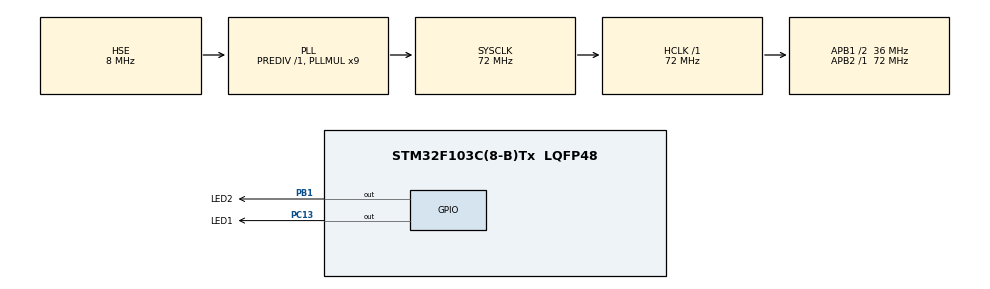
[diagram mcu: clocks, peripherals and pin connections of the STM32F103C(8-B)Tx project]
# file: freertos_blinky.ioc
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Mcu.Family=STM32F1
RCC.PLLSourceVirtual=RCC_PLLSOURCE_HSE
PC15-OSC32_OUT.Mode=LSE-External-Oscillator
FREERTOS.Tasks01=defaultTask,8,128,StartDefaultTask,Default,NULL,Dynamic,NULL,NULL
PD1-OSC_OUT.Mode=HSE-External-Oscillator
PC13-TAMPER-RTC.Signal=GPIO_Output
NVIC.TIM1_UP_IRQn=true\:0\:0\:false\:false\:true\:false\:false\:true
PD0-OSC_IN.Signal=RCC_OSC_IN
RCC.APB1CLKDivider=RCC_HCLK_DIV2
PC14-OSC32_IN.Signal=RCC_OSC32_IN
RCC.SYSCLKSource=RCC_SYSCLKSOURCE_PLLCLK
ProjectManager.StackSize=0x400
VP_FREERTOS_VS_CMSIS_V2.Mode=CMSIS_V2
PD1-OSC_OUT.Signal=RCC_OSC_OUT
PA13.Signal=SYS_JTMS-SWDIO
ProjectManager.TargetToolchain=STM32CubeIDE
RCC.HCLKFreq_Value=72000000
RCC.APB2TimFreq_Value=72000000
RCC.USBFreq_Value=72000000
PC15-OSC32_OUT.Signal=RCC_OSC32_OUT
RCC.AHBFreq_Value=72000000
PD0-OSC_IN.Mode=HSE-External-Oscillator
board=custom
PC13-TAMPER-RTC.GPIO_Label=LED1
RCC.PLLMUL=RCC_PLL_MUL9
RCC.APB2Freq_Value=72000000
PC14-OSC32_IN.Mode=LSE-External-Oscillator
PC13-TAMPER-RTC.PinState=GPIO_PIN_SET
PA14.Mode=Serial_Wire
VP_SYS_VS_tim1.Mode=TIM1
PB1.GPIO_Label=LED2
PA13.Mode=Serial_Wire
Mcu.Name=STM32F103C(8-B)Tx
PB1.PinState=GPIO_PIN_SET
RCC.SYSCLKFreq_VALUE=72000000
Mcu.Package=LQFP48
PB1.Signal=GPIO_Output
NVIC.TimeBase=TIM1_UP_IRQn
NVIC.TimeBaseIP=TIM1
PA14.Signal=SYS_JTCK-SWCLK
ProjectManager.HeapSize=0x200
NVIC.PriorityGroup=NVIC_PRIORITYGROUP_4
RCC.APB1TimFreq_Value=72000000
RCC.APB1Freq_Value=36000000

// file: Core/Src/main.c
/* USER CODE BEGIN Header */
/**
 ******************************************************************************
 * @file           : main.c
 * @brief          : Main program body
 ******************************************************************************
 * @attention
 *
 * <h2><center>&copy; Copyright (c) 2021 STMicroelectronics.
 * All rights reserved.</center></h2>
 *
 * This software component is licensed by ST under BSD 3-Clause license,
 * the "License"; You may not use this file except in compliance with the
 * License. You may obtain a copy of the License at:
 *                        opensource.org/licenses/BSD-3-Clause
 *
 ******************************************************************************
 */
/* USER CODE END Header */
#include "main.h"
#include "cmsis_os.h"

/* USER CODE BEGIN Includes */
#include "task.h"
/* USER CODE END Includes */

/* USER CODE BEGIN PTD */
typedef struct {
	GPIO_TypeDef *led_gpio_port;
	uint16_t led_gpio_pin;
	uint32_t tiempo;
} task_param_t;
/* USER CODE END PTD */

/* Definitions for defaultTask */
osThreadId_t defaultTaskHandle;
const osThreadAttr_t defaultTask_attributes = {
		.name = "defaultTask",
		.stack_size = 128 * 4,
		.priority = (osPriority_t) osPriorityLow,
};
/* USER CODE BEGIN PV */

static task_param_t task_param1 = {
		.led_gpio_port = LED1_GPIO_Port,
		.led_gpio_pin = LED1_Pin,
		.tiempo = 100
};

static task_param_t task_param2 = {
		.led_gpio_port = LED2_GPIO_Port,
		.led_gpio_pin = LED2_Pin,
		.tiempo = 700
};

/* USER CODE END PV */

void SystemClock_Config(void);
static void MX_GPIO_Init(void);
void StartDefaultTask(void *argument);

/* USER CODE BEGIN 0 */

static void task(void *a)
{
	task_param_t *task_param = (task_param_t *)a;

	while (1) {
		HAL_GPIO_TogglePin(task_param->led_gpio_port, task_param->led_gpio_pin);
		vTaskDelay(task_param->tiempo / portTICK_RATE_MS);
	}
}

/* USER CODE END 0 */

int main(void)
{

	/* MCU Configuration--------------------------------------------------------*/

	/* Reset of all peripherals, Initializes the Flash interface and the Systick. */
	HAL_Init();

	/* Configure the system clock */
	SystemClock_Config();

	/* Initialize all configured peripherals */
	MX_GPIO_Init();

	/* Init scheduler */
	osKernelInitialize();

	/* Create the thread(s) */
	/* creation of defaultTask */
	defaultTaskHandle = osThreadNew(StartDefaultTask, NULL, &defaultTask_attributes);

	/* USER CODE BEGIN RTOS_THREADS */
	xTaskCreate(task, (const char *)"task_1",
			configMINIMAL_STACK_SIZE*2, &task_param1, osPriorityNormal, 0);

	xTaskCreate(task, (const char *)"task_2",
			configMINIMAL_STACK_SIZE*2, &task_param2, osPriorityNormal, 0);
	/* USER CODE END RTOS_THREADS */

	/* Start scheduler */
	osKernelStart();

	/* We should never get here as control is now taken by the scheduler */
	/* Infinite loop */
	while (1)
	{

	}
}

void SystemClock_Config(void)
{
	RCC_OscInitTypeDef RCC_OscInitStruct = {0};
	RCC_ClkInitTypeDef RCC_ClkInitStruct = {0};

	/** Initializes the RCC Oscillators according to the specified parameters
	 * in the RCC_OscInitTypeDef structure.
	 */
	RCC_OscInitStruct.OscillatorType = RCC_OSCILLATORTYPE_HSE;
	RCC_OscInitStruct.HSEState = RCC_HSE_ON;
	RCC_OscInitStruct.HSEPredivValue = RCC_HSE_PREDIV_DIV1;
	RCC_OscInitStruct.HSIState = RCC_HSI_ON;
	RCC_OscInitStruct.PLL.PLLState = RCC_PLL_ON;
	RCC_OscInitStruct.PLL.PLLSource = RCC_PLLSOURCE_HSE;
	RCC_OscInitStruct.PLL.PLLMUL = RCC_PLL_MUL9;
	if (HAL_RCC_OscConfig(&RCC_OscInitStruct) != HAL_OK)
	{
		Error_Handler();
	}
	/** Initializes the CPU, AHB and APB buses clocks
	 */
	RCC_ClkInitStruct.ClockType = RCC_CLOCKTYPE_HCLK|RCC_CLOCKTYPE_SYSCLK
			|RCC_CLOCKTYPE_PCLK1|RCC_CLOCKTYPE_PCLK2;
	RCC_ClkInitStruct.SYSCLKSource = RCC_SYSCLKSOURCE_PLLCLK;
	RCC_ClkInitStruct.AHBCLKDivider = RCC_SYSCLK_DIV1;
	RCC_ClkInitStruct.APB1CLKDivider = RCC_HCLK_DIV2;
	RCC_ClkInitStruct.APB2CLKDivider = RCC_HCLK_DIV1;

	if (HAL_RCC_ClockConfig(&RCC_ClkInitStruct, FLASH_LATENCY_2) != HAL_OK)
	{
		Error_Handler();
	}
}

static void MX_GPIO_Init(void)
{
	GPIO_InitTypeDef GPIO_InitStruct = {0};

	/* GPIO Ports Clock Enable */
	__HAL_RCC_GPIOC_CLK_ENABLE();
	__HAL_RCC_GPIOD_CLK_ENABLE();
	__HAL_RCC_GPIOB_CLK_ENABLE();
	__HAL_RCC_GPIOA_CLK_ENABLE();

	/*Configure GPIO pin Output Level */
	HAL_GPIO_WritePin(LED1_GPIO_Port, LED1_Pin, GPIO_PIN_SET);

	/*Configure GPIO pin Output Level */
	HAL_GPIO_WritePin(LED2_GPIO_Port, LED2_Pin, GPIO_PIN_SET);

	/*Configure GPIO pin : LED1_Pin */
	GPIO_InitStruct.Pin = LED1_Pin;
	GPIO_InitStruct.Mode = GPIO_MODE_OUTPUT_PP;
	GPIO_InitStruct.Pull = GPIO_NOPULL;
	GPIO_InitStruct.Speed = GPIO_SPEED_FREQ_LOW;
	HAL_GPIO_Init(LED1_GPIO_Port, &GPIO_InitStruct);

	/*Configure GPIO pin : LED2_Pin */
	GPIO_InitStruct.Pin = LED2_Pin;
	GPIO_InitStruct.Mode = GPIO_MODE_OUTPUT_PP;
	GPIO_InitStruct.Pull = GPIO_NOPULL;
	GPIO_InitStruct.Speed = GPIO_SPEED_FREQ_LOW;
	HAL_GPIO_Init(LED2_GPIO_Port, &GPIO_InitStruct);

}

void StartDefaultTask(void *argument)
{
	/* USER CODE BEGIN 5 */
	/* Infinite loop */
	for(;;)
	{
		osDelay(1000);
	}
	/* USER CODE END 5 */
}

void HAL_TIM_PeriodElapsedCallback(TIM_HandleTypeDef *htim)
{
	if (htim->Instance == TIM1) {
		HAL_IncTick();
	}
}

void Error_Handler(void)
{
	__disable_irq();
	while (1)
	{
	}
}

/************************ (C) COPYRIGHT STMicroelectronics *****END OF FILE****/
